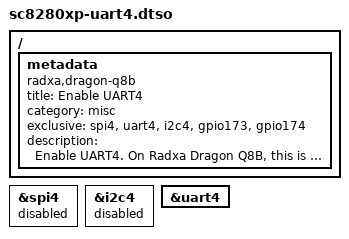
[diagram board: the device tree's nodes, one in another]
// SPDX-License-Identifier: BSD-3-Clause
/*
 * Copyright (c) 2026 Radxa Computer (Shenzhen) Co., Ltd.
 */

/dts-v1/;
/plugin/;

/ {
	metadata {
		title = "Enable UART4";
		compatible = "radxa,dragon-q8b";
		category = "misc";
		exclusive = "spi4", "uart4", "i2c4", "gpio173", "gpio174";
		description = "Enable UART4.
On Radxa Dragon Q8B, this is pin 40(tx), 12(rx).";
	};
};

&spi4 {
	status = "disabled";
};

&i2c4 {
	status = "disabled";
};

&uart4 {
	status = "okay";
};
